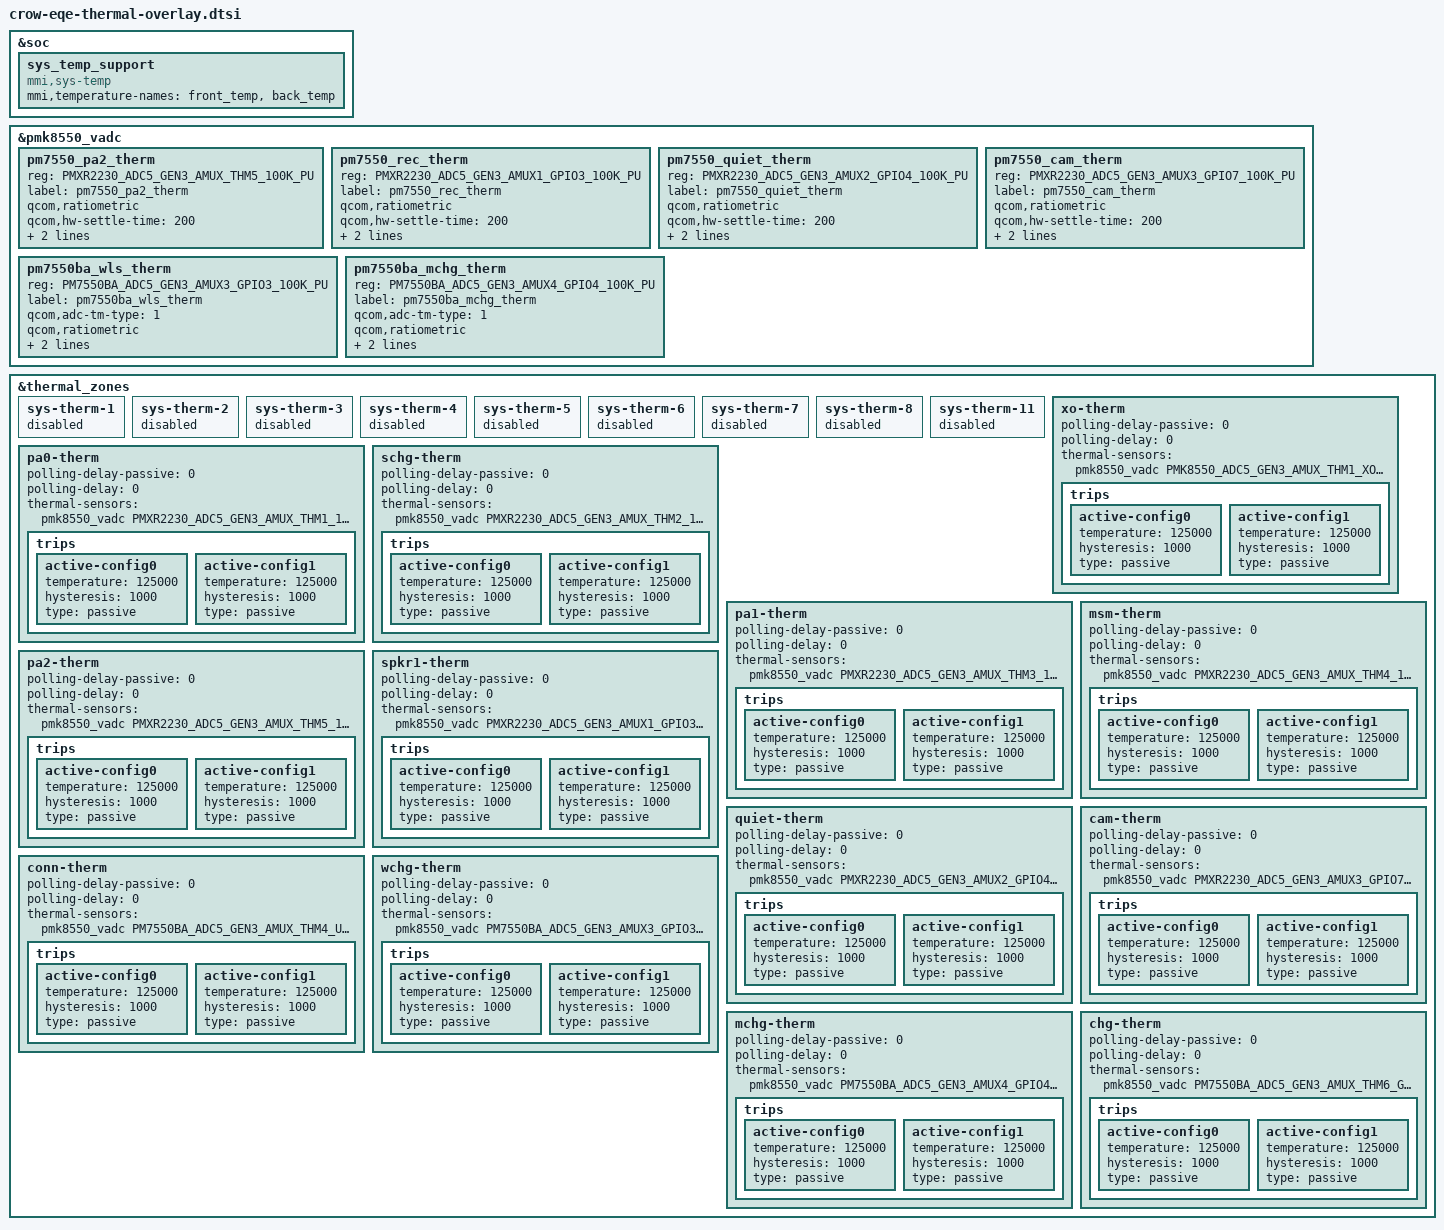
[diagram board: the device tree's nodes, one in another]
/* eqe thermal dts*/
&soc {
        sys_temp_support {
                compatible = "mmi,sys-temp";
                mmi,temperature-names = "front_temp",
                        "back_temp";
                status = "ok";
        };
};

&pmk8550_vadc {
	pm7550_pa2_therm {
		reg = <PMXR2230_ADC5_GEN3_AMUX_THM5_100K_PU>;
		label = "pm7550_pa2_therm";
		qcom,ratiometric;
		qcom,hw-settle-time = <200>;
		qcom,pre-scaling = <1 1>;
		qcom,adc-tm-type = <1>;
	};

	pm7550_rec_therm {
		reg = <PMXR2230_ADC5_GEN3_AMUX1_GPIO3_100K_PU>;
		label = "pm7550_rec_therm";
		qcom,ratiometric;
		qcom,hw-settle-time = <200>;
		qcom,pre-scaling = <1 1>;
		qcom,adc-tm-type = <1>;
	};

	pm7550_quiet_therm {
		reg = <PMXR2230_ADC5_GEN3_AMUX2_GPIO4_100K_PU>;
		label = "pm7550_quiet_therm";
		qcom,ratiometric;
		qcom,hw-settle-time = <200>;
		qcom,pre-scaling = <1 1>;
		qcom,adc-tm-type = <1>;
	};

	pm7550_cam_therm {
		reg = <PMXR2230_ADC5_GEN3_AMUX3_GPIO7_100K_PU>;
		label = "pm7550_cam_therm";
		qcom,ratiometric;
		qcom,hw-settle-time = <200>;
		qcom,pre-scaling = <1 1>;
		qcom,adc-tm-type = <1>;
	};

	pm7550ba_wls_therm {
		reg = <PM7550BA_ADC5_GEN3_AMUX3_GPIO3_100K_PU>;
		label = "pm7550ba_wls_therm";
		qcom,adc-tm-type = <1>;
		qcom,ratiometric;
		qcom,hw-settle-time = <200>;
		qcom,pre-scaling = <1 1>;
	};

	pm7550ba_mchg_therm {
		reg = <PM7550BA_ADC5_GEN3_AMUX4_GPIO4_100K_PU>;
		label = "pm7550ba_mchg_therm";
		qcom,adc-tm-type = <1>;
		qcom,ratiometric;
		qcom,hw-settle-time = <200>;
		qcom,pre-scaling = <1 1>;
	};
};

&thermal_zones {
	sys-therm-1 {
		status = "disabled";
	};

	sys-therm-2 {
		status = "disabled";
	};

	sys-therm-3 {
		status = "disabled";
	};

	sys-therm-4 {
		status = "disabled";
	};

	sys-therm-5 {
		status = "disabled";
	};

	sys-therm-6 {
		status = "disabled";
	};

	sys-therm-7 {
		status = "disabled";
	};

	sys-therm-8 {
		status = "disabled";
	};

	sys-therm-11 {
		status = "disabled";
	};

	/* PMK7550 AMUX config xo-therm */
	xo-therm {
		polling-delay-passive = <0>;
		polling-delay = <0>;
		thermal-sensors = <&pmk8550_vadc PMK8550_ADC5_GEN3_AMUX_THM1_XO_THERM_100K_PU>;
		trips {
			active-config0 {
				temperature = <125000>;
				hysteresis = <1000>;
				type = "passive";
			};

			active-config1 {
				temperature = <125000>;
				hysteresis = <1000>;
				type = "passive";
			};
		};
	};

	/* PM7550 AMUX config amux1~amux5, gpio3,4,7*/
	pa0-therm {
		polling-delay-passive = <0>;
		polling-delay = <0>;
		thermal-sensors = <&pmk8550_vadc PMXR2230_ADC5_GEN3_AMUX_THM1_100K_PU>;
		trips {
			active-config0 {
				temperature = <125000>;
				hysteresis = <1000>;
				type = "passive";
			};

			active-config1 {
				temperature = <125000>;
				hysteresis = <1000>;
				type = "passive";
			};
		};
	};

	schg-therm {
		polling-delay-passive = <0>;
		polling-delay = <0>;
		thermal-sensors = <&pmk8550_vadc PMXR2230_ADC5_GEN3_AMUX_THM2_100K_PU>;
		trips {
			active-config0 {
				temperature = <125000>;
				hysteresis = <1000>;
				type = "passive";
			};

			active-config1 {
				temperature = <125000>;
				hysteresis = <1000>;
				type = "passive";
			};
		};
	};

	pa1-therm {
		polling-delay-passive = <0>;
		polling-delay = <0>;
		thermal-sensors = <&pmk8550_vadc PMXR2230_ADC5_GEN3_AMUX_THM3_100K_PU>;
		trips {
			active-config0 {
				temperature = <125000>;
				hysteresis = <1000>;
				type = "passive";
			};

			active-config1 {
				temperature = <125000>;
				hysteresis = <1000>;
				type = "passive";
			};
		};
	};

	msm-therm {
		polling-delay-passive = <0>;
		polling-delay = <0>;
		thermal-sensors = <&pmk8550_vadc PMXR2230_ADC5_GEN3_AMUX_THM4_100K_PU>;
		trips {
			active-config0 {
				temperature = <125000>;
				hysteresis = <1000>;
				type = "passive";
			};

			active-config1 {
				temperature = <125000>;
				hysteresis = <1000>;
				type = "passive";
			};
		};
	};

	pa2-therm {
		polling-delay-passive = <0>;
		polling-delay = <0>;
		thermal-sensors = <&pmk8550_vadc PMXR2230_ADC5_GEN3_AMUX_THM5_100K_PU>;
		trips {
			active-config0 {
				temperature = <125000>;
				hysteresis = <1000>;
				type = "passive";
			};

			active-config1 {
				temperature = <125000>;
				hysteresis = <1000>;
				type = "passive";
			};
		};
	};

	spkr1-therm {
		polling-delay-passive = <0>;
		polling-delay = <0>;
		thermal-sensors = <&pmk8550_vadc PMXR2230_ADC5_GEN3_AMUX1_GPIO3_100K_PU>;
		trips {
			active-config0 {
				temperature = <125000>;
				hysteresis = <1000>;
				type = "passive";
			};

			active-config1 {
				temperature = <125000>;
				hysteresis = <1000>;
				type = "passive";
			};
		};
	};

	quiet-therm {
		polling-delay-passive = <0>;
		polling-delay = <0>;
		thermal-sensors = <&pmk8550_vadc PMXR2230_ADC5_GEN3_AMUX2_GPIO4_100K_PU>;
		trips {
			active-config0 {
				temperature = <125000>;
				hysteresis = <1000>;
				type = "passive";
			};

			active-config1 {
				temperature = <125000>;
				hysteresis = <1000>;
				type = "passive";
			};
		};
	};

	cam-therm {
		polling-delay-passive = <0>;
		polling-delay = <0>;
		thermal-sensors = <&pmk8550_vadc PMXR2230_ADC5_GEN3_AMUX3_GPIO7_100K_PU>;
		trips {
			active-config0 {
				temperature = <125000>;
				hysteresis = <1000>;
				type = "passive";
			};

			active-config1 {
				temperature = <125000>;
				hysteresis = <1000>;
				type = "passive";
			};
		};
	};

	/* PM7550BA AMUX config usb_therm, gpio3,4,6*/
	conn-therm {
		polling-delay-passive = <0>;
		polling-delay = <0>;
		thermal-sensors = <&pmk8550_vadc PM7550BA_ADC5_GEN3_AMUX_THM4_USB_THERM_100K_PU>;
		trips {
			active-config0 {
				temperature = <125000>;
				hysteresis = <1000>;
				type = "passive";
			};

			active-config1 {
				temperature = <125000>;
				hysteresis = <1000>;
				type = "passive";
			};
		};
	};

	wchg-therm {
		polling-delay-passive = <0>;
		polling-delay = <0>;
		thermal-sensors = <&pmk8550_vadc PM7550BA_ADC5_GEN3_AMUX3_GPIO3_100K_PU>;
		trips {
			active-config0 {
				temperature = <125000>;
				hysteresis = <1000>;
				type = "passive";
			};

			active-config1 {
				temperature = <125000>;
				hysteresis = <1000>;
				type = "passive";
			};
		};
	};

	mchg-therm {
		polling-delay-passive = <0>;
		polling-delay = <0>;
		thermal-sensors = <&pmk8550_vadc PM7550BA_ADC5_GEN3_AMUX4_GPIO4_100K_PU>;
		trips {
			active-config0 {
				temperature = <125000>;
				hysteresis = <1000>;
				type = "passive";
			};

			active-config1 {
				temperature = <125000>;
				hysteresis = <1000>;
				type = "passive";
			};
		};
	};

	chg-therm {
		polling-delay-passive = <0>;
		polling-delay = <0>;
		thermal-sensors = <&pmk8550_vadc PM7550BA_ADC5_GEN3_AMUX_THM6_GPIO6_100K_PU>;
		trips {
			active-config0 {
				temperature = <125000>;
				hysteresis = <1000>;
				type = "passive";
			};

			active-config1 {
				temperature = <125000>;
				hysteresis = <1000>;
				type = "passive";
			};
		};
	};

};
